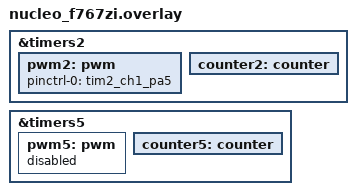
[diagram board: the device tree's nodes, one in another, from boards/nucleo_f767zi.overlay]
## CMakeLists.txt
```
# Copyright (c) 2021-2023 TiaC Systems
# Copyright (c) 2019-2021 Li-Pro.Net
# SPDX-License-Identifier: Apache-2.0

cmake_minimum_required(VERSION 3.20.0)

# Standard Bridle application boilerplate, includes Zephyr.
find_package(Zephyr REQUIRED HINTS $ENV{ZEPHYR_BASE})
project("STM Timers" VERSION 0.1)

assert(CONFIG_SHELL "Zephyr's embedded shell must be enabled")

# Add your source file to the "app" target. This must come after
# the boilerplate code, which defines the target.
target_sources(app PRIVATE src/main.c)
```

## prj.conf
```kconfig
# Copyright (c) 2021-2023 TiaC Systems
# Copyright (c) 2019-2021 Li-Pro.Net
# SPDX-License-Identifier: Apache-2.0

# Multi-threaded, with timer support in the kernel
CONFIG_MULTITHREADING=y
CONFIG_NUM_COOP_PRIORITIES=16
CONFIG_NUM_METAIRQ_PRIORITIES=0

CONFIG_ERRNO=y
CONFIG_SCHED_DUMB=y
CONFIG_WAITQ_DUMB=y

# shell with log, getopt and full command set
CONFIG_BOOT_BANNER=y
CONFIG_PRINTK=y
CONFIG_LOG=y
CONFIG_LOG_CMDS=y
CONFIG_SHELL=y
CONFIG_SHELL_GETOPT=y
CONFIG_SHELL_HELP=y
CONFIG_KERNEL_SHELL=y
CONFIG_DEVMEM_SHELL=y
CONFIG_DEVICE_SHELL=y

# shell with hwinfo, regulator, and counter commands
# CONFIG_HWINFO=y
# CONFIG_HWINFO_SHELL=y
# CONFIG_REGULATOR=y
# CONFIG_REGULATOR_SHELL=y
CONFIG_COUNTER=y
CONFIG_COUNTER_SHELL=y

# shell with eeprom, flash, led, rtc, and sensor commands
# CONFIG_EEPROM=y
# CONFIG_EEPROM_SHELL=y
# CONFIG_FLASH=y
# CONFIG_FLASH_SHELL=y
# CONFIG_LED=y
# CONFIG_LED_SHELL=y
# CONFIG_RTC=y
# CONFIG_RTC_SHELL=y
# CONFIG_SENSOR=y
# CONFIG_SENSOR_INFO=y
# CONFIG_SENSOR_SHELL=y
# CONFIG_INPUT=y
# CONFIG_INPUT_EVENT_DUMP=y
# CONFIG_INPUT_SHELL=y

# shell with adc, dac, pwm, gpio, and i2c commands
# CONFIG_ADC=y
# CONFIG_ADC_SHELL=y
CONFIG_DAC=y
# CONFIG_DAC_SHELL=y
CONFIG_PWM=y
# CONFIG_PWM_SHELL=y
CONFIG_GPIO=y
# CONFIG_GPIO_SHELL=y
CONFIG_I2C=y
# CONFIG_I2C_SHELL=y
CONFIG_COUNTER=y
# CONFIG_COUNTER_SHELL=y
CONFIG_STEPPER=y
CONFIG_STEPPER_SHELL=y
# CONFIG_POLL=y
# CONFIG_GPIO_STEPPER=y
CONFIG_STEPPER_STEP_DIR_GENERATE_ISR_SAFE_EVENTS=y

CONFIG_PINCTRL=y
CONFIG_PINCTRL_DYNAMIC=y
```

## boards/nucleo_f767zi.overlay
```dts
/*
 * Copyright (c) 2023-2024 TiaC Systems
 * SPDX-License-Identifier: Apache-2.0
 */

#include <zephyr/dt-bindings/gpio/gpio.h>

// &i2c1 {
// 	status = "okay";

// 	mcp4726: mcp4726@60 {
// 		status = "okay";
// 		compatible = "microchip,mcp4725";
// 		reg = <0x60>;

// 		#io-channel-cells = <1>;
// 	};
// };

// / {

// 	drv8424: drv8424 {
// 		status = "okay";
// 		compatible = "ti,drv8424";
// 		//  acceleration = <200>;


// 		dir-gpios = <&arduino_header 18 0>; /* D12 */
// 		step-gpios = <&arduino_header 19 0>; /* D13 */
// 		sleep-gpios = <&arduino_header 15 GPIO_ACTIVE_LOW>; /* D9 */
// 		en-gpios = <&arduino_header 14 0>; /* D8 */
// 		m0-gpios = <&arduino_header 12 0>;
// 		m1-gpios = <&arduino_header 13 0>;
// 		// timing-source = "counter";

// 		counter = <&counter2>;
// 		// acceleration = <1600>;


// 	};
// };



&timers2 {
	status = "okay";
	pwm2: pwm {
		status = "okay";
		pinctrl-0 = <&tim2_ch1_pa5>;
		pinctrl-names = "default";
	};
	counter2: counter {
		status = "okay";
		//  pinctrl-0 = <&tim2_ch1_pa0>;
	};
};

&timers5 {
	status = "okay";
	pwm5: pwm {
		status = "disabled";
	};
	counter5: counter {
		status = "okay";
	};
};
```

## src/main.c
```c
/*
 * Copyright (c) 2021-2024 TiaC Systems
 * Copyright (c) 2019-2021 Li-Pro.Net
 * Copyright (c) 2012-2014 Wind River Systems, Inc.
 * SPDX-License-Identifier: Apache-2.0
 */

#include <zephyr/kernel.h>
#include <zephyr/init.h>
#include "stm32f7xx_ll_tim.h"
#include "zephyr/devicetree.h"
#include "zephyr/device.h"
#include "zephyr/drivers/pinctrl.h"
#include "zephyr/drivers/pwm.h"
#include "zephyr/drivers/stepper.h"
#include <math.h>
#include <stdbool.h>
#include <stdint.h>
#include <zephyr/sys/printk.h>
#include <zephyr/drivers/gpio.h>
#include <zephyr/drivers/counter.h>
#include <zephyr/drivers/dac.h>
#include <zephyr/shell/shell.h>

#include <stm32_ll_rcc.h>
// #include <stm32f767xx.h>

const struct device *counter2 = DEVICE_DT_GET(DT_NODELABEL(counter2));
const struct device *counter5 = DEVICE_DT_GET(DT_NODELABEL(counter5));
// const struct device *pwm2 = DEVICE_DT_GET(DT_NODELABEL(pwm2));
// const struct device *stepper = DEVICE_DT_GET(DT_NODELABEL(drv8424));
// const struct device *dac = DEVICE_DT_GET(DT_NODELABEL(mcp4726));

void test_callback(const struct device *dev, void *user_data)
{

	// pwm_set_cycles(pwm2, 1, 1, 1, 0);
	// counter_stop(counter2);
	printk("Ping\n");
}

TIM_TypeDef *TIMx5 = ((TIM_TypeDef *)DT_REG_ADDR(DT_NODELABEL(timers5)));

TIM_TypeDef *TIMx2 = ((TIM_TypeDef *)DT_REG_ADDR(DT_NODELABEL(timers2)));

/* Empty main */
int main(void)
{
	int ret;
	// ret = dac_write_value(dac, 0, 2045);
	// printk("Dac Write Return Value: %i\n", ret);
	// ret = stepper_enable(stepper, true);
	// printk("Stepper Enable Return Value: %i\n", ret);
	// stepper_set_micro_step_res(stepper, 1);

	// ret = pinctrl_apply_state(pcfg0, PINCTRL_STATE_DEFAULT);
	// printk("Pinctrl Return Value: %i\n", ret);

	struct counter_top_cfg cfg_tm2;
	cfg_tm2.flags = 0;
	cfg_tm2.ticks = counter_us_to_ticks(counter2, 1000*5); // 200 Ticks/s
	cfg_tm2.callback = NULL;
	cfg_tm2.user_data = NULL;
	counter_set_top_value(counter2, &cfg_tm2);
	// PINCTRL

	struct counter_top_cfg cfg_tm5;
	cfg_tm5.flags = 0;
	cfg_tm5.ticks = 200*60; // 200 Ticks = 1s
	cfg_tm5.callback = test_callback;
	cfg_tm5.user_data = NULL;
	// counter_set_top_value(counter2, &cfg);
	// counter_start(counter2);

	LL_TIM_EnableAllOutputs(TIMx2);
	LL_TIM_SetTriggerOutput(TIMx2, LL_TIM_TRGO_UPDATE); // CR2-MMS - Update

	LL_TIM_EnableMasterSlaveMode(TIMx5);			// SMCR-MSM 1

	LL_TIM_SetTriggerInput(TIMx5, LL_TIM_TS_ITR0);              // SMCR-TS 000
	LL_TIM_SetClockSource(TIMx5, LL_TIM_CLOCKSOURCE_EXT_MODE1); // SMCR-SMS 0111
	counter_set_top_value(counter5, &cfg_tm5);
	counter_start(counter5);

	counter_start(counter2);

	return 0;
}
```
